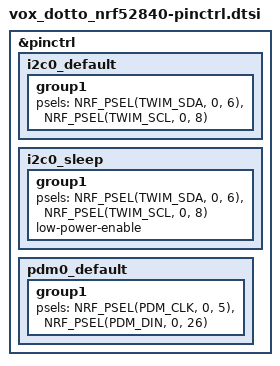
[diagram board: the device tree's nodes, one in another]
/*
 * Augmental Vox (Dotto 610-00006-1) pin control.
 * I2C0 carries the KTD2026 RGB LED driver: SDA P0.6, SCL P0.8 (per mouthpadv1
 * config_vox_dotto_610_6_1).
 */

&pinctrl {
	i2c0_default: i2c0_default {
		group1 {
			psels = <NRF_PSEL(TWIM_SDA, 0, 6)>,
				<NRF_PSEL(TWIM_SCL, 0, 8)>;
		};
	};

	i2c0_sleep: i2c0_sleep {
		group1 {
			psels = <NRF_PSEL(TWIM_SDA, 0, 6)>,
				<NRF_PSEL(TWIM_SCL, 0, 8)>;
			low-power-enable;
		};
	};

	/* PDM microphone: CLK P0.05, DIN P0.26 (per config_vox_dotto_610_6_1). */
	pdm0_default: pdm0_default {
		group1 {
			psels = <NRF_PSEL(PDM_CLK, 0, 5)>,
				<NRF_PSEL(PDM_DIN, 0, 26)>;
		};
	};
};
